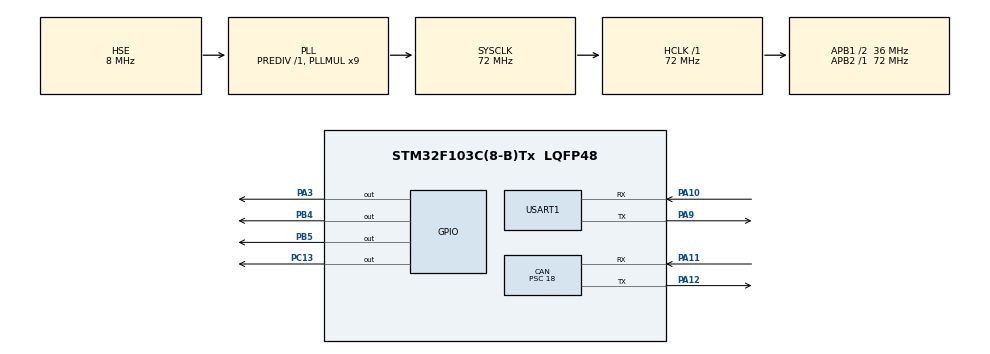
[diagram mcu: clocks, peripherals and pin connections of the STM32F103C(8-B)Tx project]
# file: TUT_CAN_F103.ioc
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CAN.BS1=CAN_BS1_2TQ
CAN.CalculateBaudRate=500000
CAN.CalculateTimeBit=2000
CAN.CalculateTimeQuantum=500.0
CAN.Prescaler=18
Mcu.Family=STM32F1
Mcu.Name=STM32F103C(8-B)Tx
Mcu.Package=LQFP48
NVIC.CAN1_RX1_IRQn=true\:0\:0\:false\:false\:true\:true\:true\:true
NVIC.PriorityGroup=NVIC_PRIORITYGROUP_4
NVIC.USART1_IRQn=true\:0\:0\:false\:false\:true\:true\:true\:true
PA10.Mode=Asynchronous
PA10.Signal=USART1_RX
PA11.Mode=CAN_Activate
PA11.Signal=CAN_RX
PA12.Mode=CAN_Activate
PA12.Signal=CAN_TX
PA13.Mode=Serial_Wire
PA13.Signal=SYS_JTMS-SWDIO
PA14.Mode=Serial_Wire
PA14.Signal=SYS_JTCK-SWCLK
PA3.Signal=GPIO_Output
PA9.Mode=Asynchronous
PA9.Signal=USART1_TX
PB4.Signal=GPIO_Output
PB5.Signal=GPIO_Output
PC13-TAMPER-RTC.Signal=GPIO_Output
PD0-OSC_IN.Mode=HSE-External-Oscillator
PD0-OSC_IN.Signal=RCC_OSC_IN
PD1-OSC_OUT.Mode=HSE-External-Oscillator
PD1-OSC_OUT.Signal=RCC_OSC_OUT
ProjectManager.HeapSize=0x200
ProjectManager.StackSize=0x400
ProjectManager.TargetToolchain=MDK-ARM V5.32
RCC.AHBFreq_Value=72000000
RCC.APB1CLKDivider=RCC_HCLK_DIV2
RCC.APB1Freq_Value=36000000
RCC.APB1TimFreq_Value=72000000
RCC.APB2Freq_Value=72000000
RCC.APB2TimFreq_Value=72000000
RCC.HCLKFreq_Value=72000000
RCC.PLLMUL=RCC_PLL_MUL9
RCC.PLLSourceVirtual=RCC_PLLSOURCE_HSE
RCC.SYSCLKFreq_VALUE=72000000
RCC.SYSCLKSource=RCC_SYSCLKSOURCE_PLLCLK
RCC.USBFreq_Value=72000000
TIM1.Prescaler=72-1
USART1.VirtualMode=VM_ASYNC
VP_CRC_VS_CRC.Mode=CRC_Activate
VP_TIM1_VS_ClockSourceINT.Mode=Internal
board=custom

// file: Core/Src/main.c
#include "main.h"
#include <stdio.h>
#include <string.h>

CAN_HandleTypeDef hcan;
CRC_HandleTypeDef hcrc;
TIM_HandleTypeDef htim1;
UART_HandleTypeDef huart1;

CAN_TxHeaderTypeDef TxHeader;
CAN_RxHeaderTypeDef RxHeader;

uint8_t TxData[8];
uint8_t RxData[8];

uint32_t TxMailbox;

void SystemClock_Config(void);
static void MX_GPIO_Init(void);
static void MX_CAN_Init(void);
static void MX_TIM1_Init(void);
static void MX_CRC_Init(void);
static void MX_USART1_UART_Init(void);

static volatile int node1 = 0, node2 = 0, node3 = 0, node4 = 0;
static volatile int flag_node1 = 0, flag_node2 = 0, flag_node3 = 0, flag_node4 = 0;

uint8_t tx_buff[] = {0, 1, 2, 3, 4, 5, 6, 7, 8, 9};
uint8_t rx_buff[24];

int main(void)
{
  HAL_Init();
  SystemClock_Config();

  MX_GPIO_Init();
  MX_CAN_Init();
  MX_TIM1_Init();
  // MX_CRC_Init();
  MX_USART1_UART_Init();

  HAL_CAN_Start(&hcan);
  HAL_CAN_ActivateNotification(&hcan, CAN_IT_RX_FIFO1_MSG_PENDING); // Activate the notification

  HAL_UART_Receive_IT(&huart1, rx_buff, 24);
//  HAL_TIM_Base_Start(&htim1);

  while (1)
  {
  }
}

void HAL_UART_RxCpltCallback(UART_HandleTypeDef *huart)
{
  if (huart->Instance == huart1.Instance)
  {
    HAL_UART_Receive_IT(&huart1, rx_buff, 24);
    if ((sscanf((char *)rx_buff, "%da%db%dc%dd", &node1, &node2, &node3, &node4)) == 4)
    {
			uint8_t in_node1, dec_node1 ,in_node2, dec_node2, in_node3, dec_node3;

			in_node1 = node1 / 100;
			if(node1 < 0)
				dec_node1 = -(node1 % 100);
			else
				dec_node1 = (node1 % 100);

			in_node2 = node2 / 100;
			if(node2 < 0)
				dec_node2 = -(node2 % 100);
			else
				dec_node2 = (node2 % 100);

			in_node3 = node3 / 100;
			if(node3 < 0)
				dec_node3 = -(node3 % 100);
			else
				dec_node3 = (node3 % 100);

      TxHeader.DLC = 6; // data length
      TxHeader.IDE = CAN_ID_STD;
      TxHeader.RTR = CAN_RTR_DATA;
      TxHeader.StdId = 0x001; // ID

      TxData[0] =  in_node1;
			TxData[1] =  dec_node1;
			TxData[2] =  in_node2;
			TxData[3] =  dec_node2;
			TxData[4] =  in_node3;
			TxData[5] =  dec_node3;

      HAL_CAN_AddTxMessage(&hcan, &TxHeader, TxData, &TxMailbox);
    }
  }
}

void HAL_CAN_RxFifo0MsgPendingCallback(CAN_HandleTypeDef *hcan)
{
  HAL_CAN_GetRxMessage(hcan, CAN_RX_FIFO0, &RxHeader, RxData);
  if (RxHeader.StdId == 0x001)
  {
    flag_node1 = 1;
  }
  else if (RxHeader.StdId == 0x002)
  {
    flag_node2 = 1;
  }
  else if (RxHeader.StdId == 0x003)
  {
    flag_node3 = 1;
  }
  else if (RxHeader.StdId == 0x004)
  {
    flag_node4 = 1;
  }
}

void SystemClock_Config(void)
{
  RCC_OscInitTypeDef RCC_OscInitStruct = {0};
  RCC_ClkInitTypeDef RCC_ClkInitStruct = {0};

  /** Initializes the RCC Oscillators according to the specified parameters
   * in the RCC_OscInitTypeDef structure.
   */
  RCC_OscInitStruct.OscillatorType = RCC_OSCILLATORTYPE_HSE;
  RCC_OscInitStruct.HSEState = RCC_HSE_ON;
  RCC_OscInitStruct.HSEPredivValue = RCC_HSE_PREDIV_DIV1;
  RCC_OscInitStruct.HSIState = RCC_HSI_ON;
  RCC_OscInitStruct.PLL.PLLState = RCC_PLL_ON;
  RCC_OscInitStruct.PLL.PLLSource = RCC_PLLSOURCE_HSE;
  RCC_OscInitStruct.PLL.PLLMUL = RCC_PLL_MUL9;
  if (HAL_RCC_OscConfig(&RCC_OscInitStruct) != HAL_OK)
  {
    Error_Handler();
  }

  /** Initializes the CPU, AHB and APB buses clocks
   */
  RCC_ClkInitStruct.ClockType = RCC_CLOCKTYPE_HCLK | RCC_CLOCKTYPE_SYSCLK | RCC_CLOCKTYPE_PCLK1 | RCC_CLOCKTYPE_PCLK2;
  RCC_ClkInitStruct.SYSCLKSource = RCC_SYSCLKSOURCE_PLLCLK;
  RCC_ClkInitStruct.AHBCLKDivider = RCC_SYSCLK_DIV1;
  RCC_ClkInitStruct.APB1CLKDivider = RCC_HCLK_DIV2;
  RCC_ClkInitStruct.APB2CLKDivider = RCC_HCLK_DIV1;

  if (HAL_RCC_ClockConfig(&RCC_ClkInitStruct, FLASH_LATENCY_2) != HAL_OK)
  {
    Error_Handler();
  }
}

static void MX_CAN_Init(void)
{

  hcan.Instance = CAN1;
  hcan.Init.Prescaler = 18;
  hcan.Init.Mode = CAN_MODE_NORMAL;
  hcan.Init.SyncJumpWidth = CAN_SJW_1TQ;
  hcan.Init.TimeSeg1 = CAN_BS1_2TQ;
  hcan.Init.TimeSeg2 = CAN_BS2_1TQ;
  hcan.Init.TimeTriggeredMode = DISABLE;
  hcan.Init.AutoBusOff = DISABLE;
  hcan.Init.AutoWakeUp = DISABLE;
  hcan.Init.AutoRetransmission = DISABLE;
  hcan.Init.ReceiveFifoLocked = DISABLE;
  hcan.Init.TransmitFifoPriority = DISABLE;
  if (HAL_CAN_Init(&hcan) != HAL_OK)
  {
    Error_Handler();
  }
  /* USER CODE BEGIN CAN_Init 2 */

  CAN_FilterTypeDef canfilterconfig;

  canfilterconfig.FilterActivation = CAN_FILTER_ENABLE;
  canfilterconfig.FilterBank = 0; // which filter bank to use from the assigned ones
  canfilterconfig.FilterFIFOAssignment = CAN_FILTER_FIFO1;
  canfilterconfig.FilterIdHigh = 0xFFF << 5;
  canfilterconfig.FilterIdLow = 0;
  canfilterconfig.FilterMaskIdHigh = 0xFFF << 5;
  canfilterconfig.FilterMaskIdLow = 0;
  canfilterconfig.FilterMode = CAN_FILTERMODE_IDMASK;
  canfilterconfig.FilterScale = CAN_FILTERSCALE_32BIT;
  canfilterconfig.SlaveStartFilterBank = 0; // doesn't matter in single can controllers

  HAL_CAN_ConfigFilter(&hcan, &canfilterconfig);

  /* USER CODE END CAN_Init 2 */
}

static void MX_CRC_Init(void)
{

  hcrc.Instance = CRC;
  if (HAL_CRC_Init(&hcrc) != HAL_OK)
  {
    Error_Handler();
  }
}

static void MX_TIM1_Init(void)
{

  TIM_ClockConfigTypeDef sClockSourceConfig = {0};
  TIM_MasterConfigTypeDef sMasterConfig = {0};

  htim1.Instance = TIM1;
  htim1.Init.Prescaler = 72 - 1;
  htim1.Init.CounterMode = TIM_COUNTERMODE_UP;
  htim1.Init.Period = 65535;
  htim1.Init.ClockDivision = TIM_CLOCKDIVISION_DIV1;
  htim1.Init.RepetitionCounter = 0;
  htim1.Init.AutoReloadPreload = TIM_AUTORELOAD_PRELOAD_DISABLE;
  if (HAL_TIM_Base_Init(&htim1) != HAL_OK)
  {
    Error_Handler();
  }
  sClockSourceConfig.ClockSource = TIM_CLOCKSOURCE_INTERNAL;
  if (HAL_TIM_ConfigClockSource(&htim1, &sClockSourceConfig) != HAL_OK)
  {
    Error_Handler();
  }
  sMasterConfig.MasterOutputTrigger = TIM_TRGO_RESET;
  sMasterConfig.MasterSlaveMode = TIM_MASTERSLAVEMODE_DISABLE;
  if (HAL_TIMEx_MasterConfigSynchronization(&htim1, &sMasterConfig) != HAL_OK)
  {
    Error_Handler();
  }
}

static void MX_USART1_UART_Init(void)
{

  huart1.Instance = USART1;
  huart1.Init.BaudRate = 115200;
  huart1.Init.WordLength = UART_WORDLENGTH_8B;
  huart1.Init.StopBits = UART_STOPBITS_1;
  huart1.Init.Parity = UART_PARITY_NONE;
  huart1.Init.Mode = UART_MODE_TX_RX;
  huart1.Init.HwFlowCtl = UART_HWCONTROL_NONE;
  huart1.Init.OverSampling = UART_OVERSAMPLING_16;
  if (HAL_UART_Init(&huart1) != HAL_OK)
  {
    Error_Handler();
  }
}

static void MX_GPIO_Init(void)
{
  GPIO_InitTypeDef GPIO_InitStruct = {0};

  /* GPIO Ports Clock Enable */
  __HAL_RCC_GPIOC_CLK_ENABLE();
  __HAL_RCC_GPIOD_CLK_ENABLE();
  __HAL_RCC_GPIOA_CLK_ENABLE();
  __HAL_RCC_GPIOB_CLK_ENABLE();

  /*Configure GPIO pin Output Level */
  HAL_GPIO_WritePin(GPIOC, GPIO_PIN_13, GPIO_PIN_RESET);

  /*Configure GPIO pin Output Level */
  HAL_GPIO_WritePin(GPIOA, GPIO_PIN_3, GPIO_PIN_RESET);

  /*Configure GPIO pin Output Level */
  HAL_GPIO_WritePin(GPIOB, GPIO_PIN_4 | GPIO_PIN_5, GPIO_PIN_RESET);

  /*Configure GPIO pin : PC13 */
  GPIO_InitStruct.Pin = GPIO_PIN_13;
  GPIO_InitStruct.Mode = GPIO_MODE_OUTPUT_PP;
  GPIO_InitStruct.Pull = GPIO_NOPULL;
  GPIO_InitStruct.Speed = GPIO_SPEED_FREQ_LOW;
  HAL_GPIO_Init(GPIOC, &GPIO_InitStruct);

  /*Configure GPIO pin : PA3 */
  GPIO_InitStruct.Pin = GPIO_PIN_3;
  GPIO_InitStruct.Mode = GPIO_MODE_OUTPUT_PP;
  GPIO_InitStruct.Pull = GPIO_NOPULL;
  GPIO_InitStruct.Speed = GPIO_SPEED_FREQ_LOW;
  HAL_GPIO_Init(GPIOA, &GPIO_InitStruct);

  /*Configure GPIO pins : PB4 PB5 */
  GPIO_InitStruct.Pin = GPIO_PIN_4 | GPIO_PIN_5;
  GPIO_InitStruct.Mode = GPIO_MODE_OUTPUT_PP;
  GPIO_InitStruct.Pull = GPIO_NOPULL;
  GPIO_InitStruct.Speed = GPIO_SPEED_FREQ_LOW;
  HAL_GPIO_Init(GPIOB, &GPIO_InitStruct);

}

void Error_Handler(void)
{
  __disable_irq();
  while (1)
  {
  }
}
